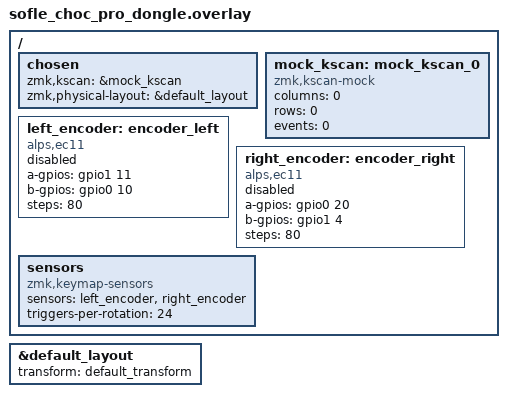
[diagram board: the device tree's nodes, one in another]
#include <dt-bindings/zmk/matrix_transform.h>
#include <dt-bindings/gpio/gpio.h>

#include "sofle_choc_pro_dongle-layouts.dtsi"

&default_layout {
    transform = <&default_transform>;
};

/ {
    chosen {
        zmk,kscan = &mock_kscan;
        zmk,physical-layout = &default_layout;
    };

    mock_kscan: mock_kscan_0 {
        compatible = "zmk,kscan-mock";
        columns = <0>;
        rows = <0>;
        events = <0>;
    };

    left_encoder: encoder_left {
        compatible = "alps,ec11";
        a-gpios = <&gpio1 11 (GPIO_ACTIVE_HIGH | GPIO_PULL_UP)>;
        b-gpios = <&gpio0 10 (GPIO_ACTIVE_HIGH | GPIO_PULL_UP)>;
        steps = <80>;
        status = "disabled";
    };

    right_encoder: encoder_right {
        compatible = "alps,ec11";
        a-gpios = <&gpio0 20 (GPIO_ACTIVE_HIGH | GPIO_PULL_UP)>;
        b-gpios = <&gpio1  4 (GPIO_ACTIVE_HIGH | GPIO_PULL_UP)>;
        steps = <80>;
        status = "disabled";
    };

    sensors: sensors {
        compatible = "zmk,keymap-sensors";
        sensors = <&left_encoder &right_encoder>;
        triggers-per-rotation = <24>;
    };
    /* ---- end optional encoder block ------------------------------------- */
};
